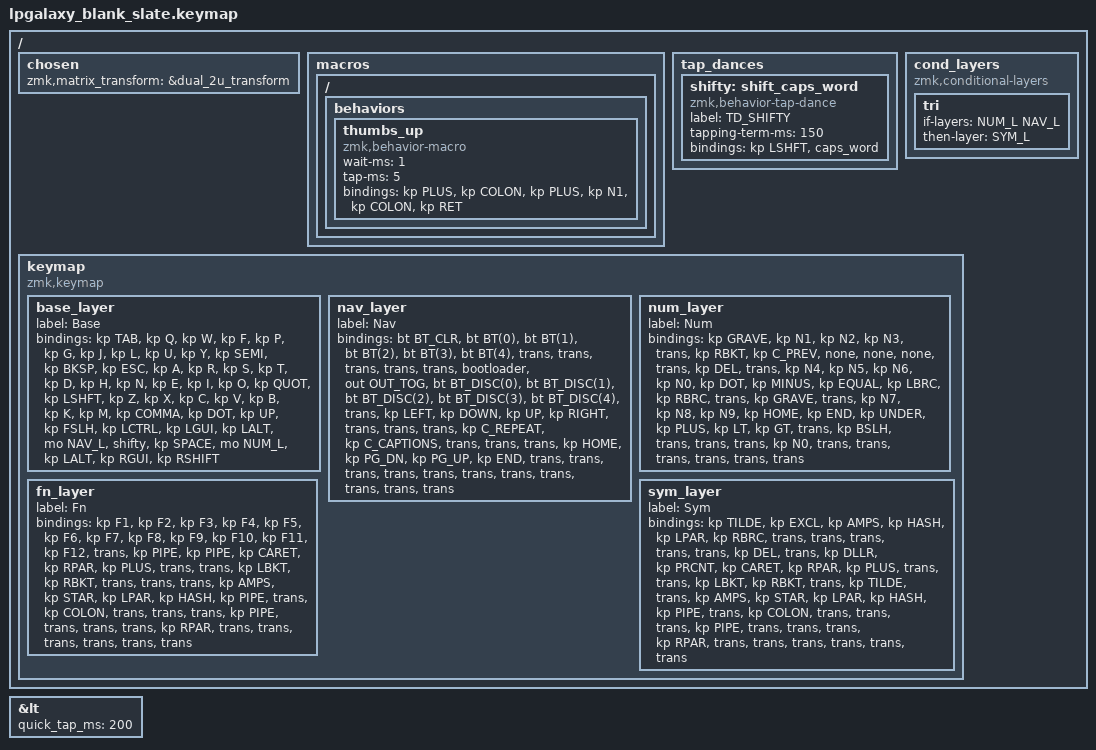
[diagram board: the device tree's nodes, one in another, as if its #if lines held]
/*
 * Copyright (c) 2022 Pete Johanson
 *
 * SPDX-License-Identifier: MIT
 */

#include <behaviors.dtsi>
#include <dt-bindings/zmk/keys.h>
#include <dt-bindings/zmk/bt.h>
#include <dt-bindings/zmk/outputs.h>

#define QWERTY_BASE 1

#define TBLE_ORTHO   1
// #define TBLE_MIT     1
// #define TBLE_DUAL_2U 1

#define NAV_L 1
#define NUM_L 2
#define SYM_L 3
#define FN_L 4

// Using layer taps on thumbs, having quick tap as well helps w/ repeating space/backspace
&lt { quick_tap_ms = <200>; };

#define BT(n) BT_SEL n

/ {
    chosen {
       zmk,matrix_transform =
#ifdef TBLE_DUAL_2U
                       &dual_2u_transform;
#elif defined(TBLE_MIT)
                       &mit_transform;
#else
                       &ortho_transform;
#endif
    };

    macros {
      ZMK_MACRO(thumbs_up,
		wait-ms = <1>;
		tap-ms = <5>;
                bindings = <&kp PLUS &kp COLON &kp PLUS &kp N1 &kp COLON &kp RET>;
		)
    };
    
    tap_dances {
    	shifty: shift_caps_word {
		compatible = "zmk,behavior-tap-dance";
		label = "TD_SHIFTY";
		#binding-cells = <0>;
		tapping-term-ms = <150>;
		bindings = <&kp LSHFT>, <&caps_word>;
	};
    };

// Conditional layer only when we have less thumb keys
#ifdef TBLE_DUAL_2U
    cond_layers {
        compatible = "zmk,conditional-layers";
	tri {
	    if-layers = <NUM_L NAV_L>;
	    then-layer = <SYM_L>;
        };
    };
#endif

    keymap {
        compatible = "zmk,keymap";

        base_layer {
            label = "Base";
            bindings = <
#ifdef QWERTY_BASE
 &kp TAB    &kp Q      &kp W      &kp F       &kp P          &kp G          &kp J            &kp L          &kp U       &kp Y      &kp SEMI      &kp BKSP
 &kp ESC    &kp A      &kp R      &kp S       &kp T          &kp D          &kp H            &kp N          &kp E       &kp I      &kp O         &kp QUOT
 &kp LSHFT  &kp Z      &kp X      &kp C       &kp V          &kp B          &kp K            &kp M          &kp COMMA   &kp DOT    &kp UP        &kp FSLH
#else
 &kp TAB    &kp Q      &kp W      &kp F       &kp P          &kp G          &kp J            &kp L          &kp U       &kp Y      &kp SEMI      &kp BKSP
 &kp ESC    &kp A      &kp R      &kp S       &kp T          &kp D          &kp H            &kp N          &kp E       &kp I      &kp O         &kp QUOT
 &kp LSHFT  &kp Z      &kp X      &kp C       &kp V          &kp B          &kp K            &kp M          &kp COMMA   &kp DOT    &kp UP        &kp FSLH
#endif
#ifdef TBLE_DUAL_2U
 &kp LCTRL  &kp LGUI   &kp LALT   &mo NAV_L       &shifty                        &kp SPACE                  &mo NUM_L   &kp LALT   &kp RGUI      &kp RSHIFT
#elif defined(TBLE_MIT)
 &kp LCTRL  &mo SYM_L   &kp LGUI  &kp LALT    &mo NAV_L         &kp SPACE                    &mo NUM_L      &kp LEFT    &kp UP     &kp DOWN      &kp RIGHT
#else
 &kp LCTRL  &mo NAV_L   &kp LGUI  &shifty     &mt LALT LPAR  &lt NUM_L SPACE &lt SYM_L RET  &mt RGUI RPAR   &kp LEFT    &kp LEFT     &kp DOWN      &kp RIGHT
#endif
            >;
        };

        nav_layer {
            label = "Nav";
            bindings = <
&bt BT_CLR	&bt BT(0)	&bt BT(1)	&bt BT(2)	&bt BT(3)	&bt BT(4)    &trans     &trans         &trans      &trans     &trans     &bootloader
&out OUT_TOG	&bt BT_DISC(0)	&bt BT_DISC(1) 	&bt BT_DISC(2)	&bt BT_DISC(3)	&bt BT_DISC(4)	&trans	&kp LEFT	&kp DOWN    &kp UP     &kp RIGHT  &trans
&trans     &trans &kp C_REPEAT &kp C_CAPTIONS   &trans      &trans    &trans     &kp HOME       &kp PG_DN   &kp PG_UP  &kp END    &trans
#ifdef TBLE_DUAL_2U
&trans  &trans        &trans     &trans              &trans                    &trans       &trans         &trans &trans &trans
#elif defined(TBLE_MIT)
&trans  &trans        &trans     &trans      &trans                &trans             &trans      &trans   &trans &kp K_VOL_UP &trans
#else
&trans  &trans        &trans     &trans      &trans          &mo FN_L       &mo FN_L    &trans  &trans	&kp C_RW &kp K_VOL_DN &kp C_FF
#endif
            >;
        };

        num_layer {
            label = "Num";
            bindings = <
&kp GRAVE	&kp N1	&kp N2	&kp N3	&trans	&kp RBKT	&kp C_PREV	&none		&none		&none		&trans	&kp DEL
&trans		&kp N4	&kp N5 	&kp N6	&kp N0	&kp DOT		&kp MINUS	&kp EQUAL	&kp LBRC	&kp RBRC	&trans	&kp GRAVE
&trans		&kp N7	&kp N8 	&kp N9	&kp HOME  &kp END	&kp UNDER	&kp PLUS	&kp LT		&kp GT		&trans	&kp BSLH
#ifdef TBLE_DUAL_2U
&trans  &trans       &trans     &kp N0              &trans                 &trans            &trans         &trans &trans &trans
#elif defined(TBLE_MIT)
&trans  &trans       &trans     &kp N0      &trans           &none            &trans        &kp DEL      &trans &trans &trans
#else
&trans  &trans       &trans     &trans     &trans    &mo FN_L         &mo FN_L     &trans      &trans      &trans &trans &trans
#endif
            >;
        };

        sym_layer {
            label = "Sym";
            bindings = <
&kp TILDE	&kp EXCL	&kp AMPS   &kp HASH    	&kp LPAR	&kp RBRC	&trans	&trans		&trans		&trans		&trans     &kp DEL
&trans     	&kp DLLR	&kp PRCNT  &kp CARET	&kp RPAR	&kp PLUS	&trans	&trans		&kp LBKT	&kp RBKT	&trans     &kp TILDE
&trans		&kp AMPS	&kp STAR   &kp LPAR     &kp HASH	&kp PIPE	&trans	&kp COLON	&trans		&trans		&trans     &kp PIPE
#ifdef TBLE_DUAL_2U
&trans &trans        &trans     &kp RPAR                &trans                    &trans       &trans         &trans &trans &trans
#elif defined(TBLE_MIT)
&trans &trans        &trans     &kp RPAR        &trans                &trans             &trans      &trans   &trans &kp PG_UP &trans
#else
&trans &trans        &trans     &trans        &trans          &mo FN_L       &mo FN_L	&trans  &trans         &kp HOME &kp PG_DN &kp END
#endif
            >;
        };


fn_layer {
            label = "Fn";
            bindings = <
&kp F1	&kp F2 &kp F3 &kp F4 &kp F5 &kp F6 &kp F7 &kp F8 &kp F9 &kp F10 &kp F11 &kp F12 
&trans     	&kp PIPE	&kp PIPE   &kp CARET	&kp RPAR	&kp PLUS	&trans	&trans		&kp LBKT	&kp RBKT	&trans     &trans
&trans		&kp AMPS	&kp STAR   &kp LPAR     &kp HASH	&kp PIPE	&trans	&kp COLON	&trans		&trans		&trans     &kp PIPE
#ifdef TBLE_DUAL_2U
&trans &trans        &trans     &kp RPAR                &trans                    &trans       &trans         &trans &trans &trans
#elif defined(TBLE_MIT)
&trans &trans        &trans     &kp RPAR        &trans                &trans             &trans      &trans   &trans &trans &trans
#else
&trans &trans        &trans     &trans        &trans          &trans       &trans    &trans  &trans         &trans &trans &trans
#endif
            >;
        };


    };
};


